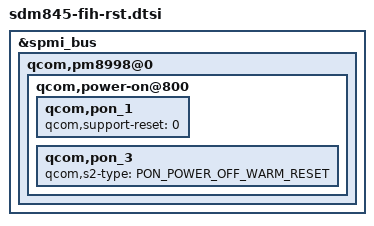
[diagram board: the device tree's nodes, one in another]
/* pm8998.dtsi
 * /proc/device-tree/soc/qcom,spmi@c440000/qcom,pm8998@0/qcom,power-on@800
 * qcom,pon_1: Disable KPDPWR_RESET
 * qcom,pon_3: Set RESIN_AND_KPDPWR_RESET be WARM_RESET to Keep Logs
 */

&spmi_bus {
	qcom,pm8998@0 {
		qcom,power-on@800 {
			/* PON: KPDPWR */
			qcom,pon_1 {
				qcom,support-reset = <0>;
			};
			/* PON: KPDPWR + RESIN */
			qcom,pon_3 {
				qcom,s2-type = <PON_POWER_OFF_WARM_RESET>;
			};
		};
	};
};
